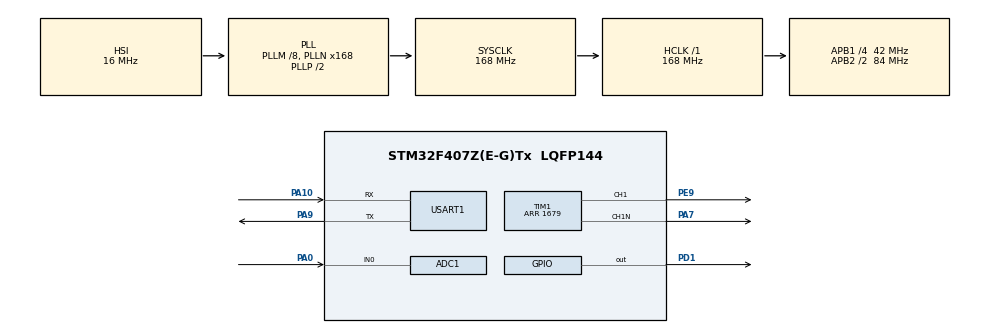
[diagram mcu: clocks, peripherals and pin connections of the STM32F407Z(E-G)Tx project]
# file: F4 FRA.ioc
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ADC1.Channel-0\#ChannelRegularConversion=ADC_CHANNEL_0
ADC1.NbrOfConversion=1
ADC1.NbrOfConversionFlag=1
ADC1.Rank-0\#ChannelRegularConversion=1
ADC1.SamplingTime-0\#ChannelRegularConversion=ADC_SAMPLETIME_3CYCLES
ADC1.master=1
Dma.Request0=USART1_TX
Dma.USART1_TX.0.Direction=DMA_MEMORY_TO_PERIPH
Dma.USART1_TX.0.FIFOMode=DMA_FIFOMODE_DISABLE
Dma.USART1_TX.0.Instance=DMA2_Stream7
Dma.USART1_TX.0.MemDataAlignment=DMA_MDATAALIGN_BYTE
Dma.USART1_TX.0.MemInc=DMA_MINC_ENABLE
Dma.USART1_TX.0.Mode=DMA_NORMAL
Dma.USART1_TX.0.PeriphDataAlignment=DMA_PDATAALIGN_BYTE
Dma.USART1_TX.0.PeriphInc=DMA_PINC_DISABLE
Dma.USART1_TX.0.Priority=DMA_PRIORITY_MEDIUM
Mcu.Family=STM32F4
Mcu.Name=STM32F407Z(E-G)Tx
Mcu.Package=LQFP144
NVIC.DMA2_Stream7_IRQn=true\:0\:0\:false\:false\:true\:false\:true\:true
NVIC.PriorityGroup=NVIC_PRIORITYGROUP_4
NVIC.TIM2_IRQn=true\:0\:0\:false\:false\:true\:true\:true\:true
NVIC.USART1_IRQn=true\:0\:0\:false\:false\:true\:true\:true\:true
PA0-WKUP.Signal=ADCx_IN0
PA10.Mode=Asynchronous
PA10.Signal=USART1_RX
PA13.Mode=JTAG_5_pins
PA13.Signal=SYS_JTMS-SWDIO
PA14.Mode=JTAG_5_pins
PA14.Signal=SYS_JTCK-SWCLK
PA15.Mode=JTAG_5_pins
PA15.Signal=SYS_JTDI
PA7.Mode=PWM Generation1 CH1 CH1N
PA7.Signal=TIM1_CH1N
PA9.Mode=Asynchronous
PA9.Signal=USART1_TX
PB3.Mode=JTAG_5_pins
PB3.Signal=SYS_JTDO-SWO
PB4.Mode=JTAG_5_pins
PB4.Signal=SYS_JTRST
PD1.Signal=GPIO_Output
PE9.Signal=S_TIM1_CH1
PH0-OSC_IN.Mode=HSE-External-Oscillator
PH0-OSC_IN.Signal=RCC_OSC_IN
PH1-OSC_OUT.Mode=HSE-External-Oscillator
PH1-OSC_OUT.Signal=RCC_OSC_OUT
ProjectManager.HeapSize=0x200
ProjectManager.StackSize=0x400
ProjectManager.TargetToolchain=MDK-ARM V5.32
RCC.48MHZClocksFreq_Value=84000000
RCC.AHBFreq_Value=168000000
RCC.APB1CLKDivider=RCC_HCLK_DIV4
RCC.APB1Freq_Value=42000000
RCC.APB1TimFreq_Value=84000000
RCC.APB2CLKDivider=RCC_HCLK_DIV2
RCC.APB2Freq_Value=84000000
RCC.APB2TimFreq_Value=168000000
RCC.CortexFreq_Value=168000000
RCC.HCLKFreq_Value=168000000
RCC.HSE_VALUE=25000000
RCC.HSI_VALUE=16000000
RCC.LSE_VALUE=32768
RCC.PLLM=8
RCC.PLLN=168
RCC.SYSCLKFreq_VALUE=168000000
RCC.SYSCLKSource=RCC_SYSCLKSOURCE_PLLCLK
RCC.VCOOutputFreq_Value=336000000
SH.ADCx_IN0.0=ADC1_IN0,IN0
SH.S_TIM1_CH1.0=TIM1_CH1,PWM Generation1 CH1 CH1N
TIM1.AutoReloadPreload=TIM_AUTORELOAD_PRELOAD_ENABLE
TIM1.Channel-PWM\ Generation1\ CH1\ CH1N=TIM_CHANNEL_1
TIM1.DeadTime=100
TIM1.OCNPolarity_1=TIM_OCNPOLARITY_HIGH
TIM1.Period=1679
TIM2.AutoReloadPreload=TIM_AUTORELOAD_PRELOAD_ENABLE
TIM2.Period=1679
USART1.VirtualMode=VM_ASYNC
VP_TIM1_VS_ClockSourceINT.Mode=Internal
VP_TIM2_VS_ClockSourceINT.Mode=Internal
board=custom

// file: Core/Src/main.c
/* USER CODE BEGIN Header */
/**
 ******************************************************************************
 * @file           : main.c
 * @brief          : Main program body
 ******************************************************************************
 * @attention
 *
 * Copyright (c) 2024 STMicroelectronics.
 * All rights reserved.
 *
 * This software is licensed under terms that can be found in the LICENSE file
 * in the root directory of this software component.
 * If no LICENSE file comes with this software, it is provided AS-IS.
 *
 ******************************************************************************
 */
/* USER CODE END Header */
#include "main.h"

/* USER CODE BEGIN Includes */
#include "FRA.h"
/* USER CODE END Includes */

ADC_HandleTypeDef hadc1;

TIM_HandleTypeDef htim1;
TIM_HandleTypeDef htim2;

UART_HandleTypeDef huart1;
DMA_HandleTypeDef hdma_usart1_tx;

void SystemClock_Config(void);
static void MX_GPIO_Init(void);
static void MX_DMA_Init(void);
static void MX_ADC1_Init(void);
static void MX_TIM1_Init(void);
static void MX_USART1_UART_Init(void);
static void MX_TIM2_Init(void);

/* USER CODE BEGIN 0 */
void tmp(TIM_HandleTypeDef*);
/* USER CODE END 0 */

int main(void)
{

  /* MCU Configuration--------------------------------------------------------*/

  /* Reset of all peripherals, Initializes the Flash interface and the Systick. */
  HAL_Init();

  /* Configure the system clock */
  SystemClock_Config();

  /* Initialize all configured peripherals */
  MX_GPIO_Init();
  MX_DMA_Init();
  MX_ADC1_Init();
  MX_TIM1_Init();
  MX_USART1_UART_Init();
  MX_TIM2_Init();
  /* USER CODE BEGIN 2 */
  struct FRAParameterBlock block;
  block.FclkMHz = 168;
  block.InjectAmplitude = 0.05;
  block.NorminalDutyCycle = 0.3;
  block.SwitchingFrequencyKHz = 100;

  HAL_TIM_PWM_Start(&htim1, TIM_CHANNEL_1);
  HAL_TIMEx_PWMN_Start(&htim1, TIM_CHANNEL_1);
  FRA_Init(&hadc1, &htim1, &htim2, &huart1, block);

  /* USER CODE END 2 */

  /* Infinite loop */
  while (1)
  {

  }
}

void SystemClock_Config(void)
{
  RCC_OscInitTypeDef RCC_OscInitStruct = {0};
  RCC_ClkInitTypeDef RCC_ClkInitStruct = {0};

  /** Configure the main internal regulator output voltage
  */
  __HAL_RCC_PWR_CLK_ENABLE();
  __HAL_PWR_VOLTAGESCALING_CONFIG(PWR_REGULATOR_VOLTAGE_SCALE1);

  /** Initializes the RCC Oscillators according to the specified parameters
  * in the RCC_OscInitTypeDef structure.
  */
  RCC_OscInitStruct.OscillatorType = RCC_OSCILLATORTYPE_HSI;
  RCC_OscInitStruct.HSIState = RCC_HSI_ON;
  RCC_OscInitStruct.HSICalibrationValue = RCC_HSICALIBRATION_DEFAULT;
  RCC_OscInitStruct.PLL.PLLState = RCC_PLL_ON;
  RCC_OscInitStruct.PLL.PLLSource = RCC_PLLSOURCE_HSI;
  RCC_OscInitStruct.PLL.PLLM = 8;
  RCC_OscInitStruct.PLL.PLLN = 168;
  RCC_OscInitStruct.PLL.PLLP = RCC_PLLP_DIV2;
  RCC_OscInitStruct.PLL.PLLQ = 4;
  if (HAL_RCC_OscConfig(&RCC_OscInitStruct) != HAL_OK)
  {
    Error_Handler();
  }

  /** Initializes the CPU, AHB and APB buses clocks
  */
  RCC_ClkInitStruct.ClockType = RCC_CLOCKTYPE_HCLK|RCC_CLOCKTYPE_SYSCLK
                              |RCC_CLOCKTYPE_PCLK1|RCC_CLOCKTYPE_PCLK2;
  RCC_ClkInitStruct.SYSCLKSource = RCC_SYSCLKSOURCE_PLLCLK;
  RCC_ClkInitStruct.AHBCLKDivider = RCC_SYSCLK_DIV1;
  RCC_ClkInitStruct.APB1CLKDivider = RCC_HCLK_DIV4;
  RCC_ClkInitStruct.APB2CLKDivider = RCC_HCLK_DIV2;

  if (HAL_RCC_ClockConfig(&RCC_ClkInitStruct, FLASH_LATENCY_5) != HAL_OK)
  {
    Error_Handler();
  }
}

static void MX_ADC1_Init(void)
{

  ADC_ChannelConfTypeDef sConfig = {0};

  /** Configure the global features of the ADC (Clock, Resolution, Data Alignment and number of conversion)
  */
  hadc1.Instance = ADC1;
  hadc1.Init.ClockPrescaler = ADC_CLOCK_SYNC_PCLK_DIV4;
  hadc1.Init.Resolution = ADC_RESOLUTION_12B;
  hadc1.Init.ScanConvMode = DISABLE;
  hadc1.Init.ContinuousConvMode = DISABLE;
  hadc1.Init.DiscontinuousConvMode = DISABLE;
  hadc1.Init.ExternalTrigConvEdge = ADC_EXTERNALTRIGCONVEDGE_NONE;
  hadc1.Init.ExternalTrigConv = ADC_SOFTWARE_START;
  hadc1.Init.DataAlign = ADC_DATAALIGN_RIGHT;
  hadc1.Init.NbrOfConversion = 1;
  hadc1.Init.DMAContinuousRequests = DISABLE;
  hadc1.Init.EOCSelection = ADC_EOC_SINGLE_CONV;
  if (HAL_ADC_Init(&hadc1) != HAL_OK)
  {
    Error_Handler();
  }

  /** Configure for the selected ADC regular channel its corresponding rank in the sequencer and its sample time.
  */
  sConfig.Channel = ADC_CHANNEL_0;
  sConfig.Rank = 1;
  sConfig.SamplingTime = ADC_SAMPLETIME_3CYCLES;
  if (HAL_ADC_ConfigChannel(&hadc1, &sConfig) != HAL_OK)
  {
    Error_Handler();
  }

}

static void MX_TIM1_Init(void)
{

  TIM_ClockConfigTypeDef sClockSourceConfig = {0};
  TIM_MasterConfigTypeDef sMasterConfig = {0};
  TIM_OC_InitTypeDef sConfigOC = {0};
  TIM_BreakDeadTimeConfigTypeDef sBreakDeadTimeConfig = {0};

  htim1.Instance = TIM1;
  htim1.Init.Prescaler = 0;
  htim1.Init.CounterMode = TIM_COUNTERMODE_UP;
  htim1.Init.Period = 1679;
  htim1.Init.ClockDivision = TIM_CLOCKDIVISION_DIV1;
  htim1.Init.RepetitionCounter = 0;
  htim1.Init.AutoReloadPreload = TIM_AUTORELOAD_PRELOAD_ENABLE;
  if (HAL_TIM_Base_Init(&htim1) != HAL_OK)
  {
    Error_Handler();
  }
  sClockSourceConfig.ClockSource = TIM_CLOCKSOURCE_INTERNAL;
  if (HAL_TIM_ConfigClockSource(&htim1, &sClockSourceConfig) != HAL_OK)
  {
    Error_Handler();
  }
  if (HAL_TIM_PWM_Init(&htim1) != HAL_OK)
  {
    Error_Handler();
  }
  sMasterConfig.MasterOutputTrigger = TIM_TRGO_RESET;
  sMasterConfig.MasterSlaveMode = TIM_MASTERSLAVEMODE_DISABLE;
  if (HAL_TIMEx_MasterConfigSynchronization(&htim1, &sMasterConfig) != HAL_OK)
  {
    Error_Handler();
  }
  sConfigOC.OCMode = TIM_OCMODE_PWM1;
  sConfigOC.Pulse = 0;
  sConfigOC.OCPolarity = TIM_OCPOLARITY_HIGH;
  sConfigOC.OCNPolarity = TIM_OCNPOLARITY_HIGH;
  sConfigOC.OCFastMode = TIM_OCFAST_DISABLE;
  sConfigOC.OCIdleState = TIM_OCIDLESTATE_RESET;
  sConfigOC.OCNIdleState = TIM_OCNIDLESTATE_RESET;
  if (HAL_TIM_PWM_ConfigChannel(&htim1, &sConfigOC, TIM_CHANNEL_1) != HAL_OK)
  {
    Error_Handler();
  }
  sBreakDeadTimeConfig.OffStateRunMode = TIM_OSSR_DISABLE;
  sBreakDeadTimeConfig.OffStateIDLEMode = TIM_OSSI_DISABLE;
  sBreakDeadTimeConfig.LockLevel = TIM_LOCKLEVEL_OFF;
  sBreakDeadTimeConfig.DeadTime = 100;
  sBreakDeadTimeConfig.BreakState = TIM_BREAK_DISABLE;
  sBreakDeadTimeConfig.BreakPolarity = TIM_BREAKPOLARITY_HIGH;
  sBreakDeadTimeConfig.AutomaticOutput = TIM_AUTOMATICOUTPUT_DISABLE;
  if (HAL_TIMEx_ConfigBreakDeadTime(&htim1, &sBreakDeadTimeConfig) != HAL_OK)
  {
    Error_Handler();
  }
  HAL_TIM_MspPostInit(&htim1);

}

static void MX_TIM2_Init(void)
{

  TIM_ClockConfigTypeDef sClockSourceConfig = {0};
  TIM_MasterConfigTypeDef sMasterConfig = {0};

  htim2.Instance = TIM2;
  htim2.Init.Prescaler = 0;
  htim2.Init.CounterMode = TIM_COUNTERMODE_UP;
  htim2.Init.Period = 1679;
  htim2.Init.ClockDivision = TIM_CLOCKDIVISION_DIV1;
  htim2.Init.AutoReloadPreload = TIM_AUTORELOAD_PRELOAD_ENABLE;
  if (HAL_TIM_Base_Init(&htim2) != HAL_OK)
  {
    Error_Handler();
  }
  sClockSourceConfig.ClockSource = TIM_CLOCKSOURCE_INTERNAL;
  if (HAL_TIM_ConfigClockSource(&htim2, &sClockSourceConfig) != HAL_OK)
  {
    Error_Handler();
  }
  sMasterConfig.MasterOutputTrigger = TIM_TRGO_RESET;
  sMasterConfig.MasterSlaveMode = TIM_MASTERSLAVEMODE_DISABLE;
  if (HAL_TIMEx_MasterConfigSynchronization(&htim2, &sMasterConfig) != HAL_OK)
  {
    Error_Handler();
  }

}

static void MX_USART1_UART_Init(void)
{

  huart1.Instance = USART1;
  huart1.Init.BaudRate = 115200;
  huart1.Init.WordLength = UART_WORDLENGTH_8B;
  huart1.Init.StopBits = UART_STOPBITS_1;
  huart1.Init.Parity = UART_PARITY_NONE;
  huart1.Init.Mode = UART_MODE_TX_RX;
  huart1.Init.HwFlowCtl = UART_HWCONTROL_NONE;
  huart1.Init.OverSampling = UART_OVERSAMPLING_16;
  if (HAL_UART_Init(&huart1) != HAL_OK)
  {
    Error_Handler();
  }

}

static void MX_DMA_Init(void)
{

  /* DMA controller clock enable */
  __HAL_RCC_DMA2_CLK_ENABLE();

  /* DMA interrupt init */
  /* DMA2_Stream7_IRQn interrupt configuration */
  HAL_NVIC_SetPriority(DMA2_Stream7_IRQn, 0, 0);
  HAL_NVIC_EnableIRQ(DMA2_Stream7_IRQn);

}

static void MX_GPIO_Init(void)
{
  GPIO_InitTypeDef GPIO_InitStruct = {0};

  /* GPIO Ports Clock Enable */
  __HAL_RCC_GPIOH_CLK_ENABLE();
  __HAL_RCC_GPIOA_CLK_ENABLE();
  __HAL_RCC_GPIOE_CLK_ENABLE();
  __HAL_RCC_GPIOD_CLK_ENABLE();
  __HAL_RCC_GPIOB_CLK_ENABLE();

  /*Configure GPIO pin Output Level */
  HAL_GPIO_WritePin(GPIOD, GPIO_PIN_1, GPIO_PIN_RESET);

  /*Configure GPIO pin : PD1 */
  GPIO_InitStruct.Pin = GPIO_PIN_1;
  GPIO_InitStruct.Mode = GPIO_MODE_OUTPUT_PP;
  GPIO_InitStruct.Pull = GPIO_NOPULL;
  GPIO_InitStruct.Speed = GPIO_SPEED_FREQ_LOW;
  HAL_GPIO_Init(GPIOD, &GPIO_InitStruct);

}

/* USER CODE BEGIN 4 */
void tmp(TIM_HandleTypeDef *htim)
{
  HAL_GPIO_TogglePin(GPIOD, GPIO_PIN_1);
}
/* USER CODE END 4 */

void Error_Handler(void)
{
  __disable_irq();
  while (1)
  {
  }
}
